VERSION ""

NS_ :

BS_:

BU_: BMS CHG

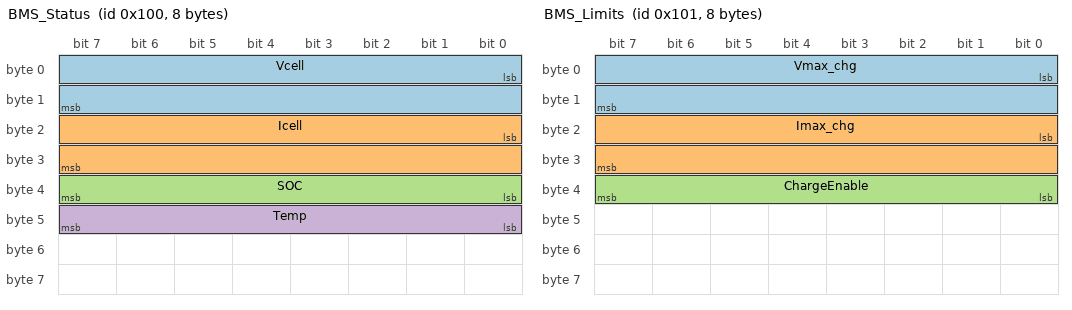
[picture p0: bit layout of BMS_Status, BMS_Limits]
BO_ 256 BMS_Status: 8 BMS
 SG_ Vcell : 0|16@1+ (0.001,0) [0|65.535] "V" CHG
 SG_ Icell : 16|16@1- (0.1,0) [-3276.8|3276.7] "A" CHG
 SG_ SOC : 32|8@1+ (0.5,0) [0|127.5] "%" CHG
 SG_ Temp : 40|8@1+ (1,-40) [-40|215] "degC" CHG

BO_ 257 BMS_Limits: 8 BMS
 SG_ Vmax_chg : 0|16@1+ (0.01,0) [0|655.35] "V" CHG
 SG_ Imax_chg : 16|16@1+ (0.1,0) [0|6553.5] "A" CHG
 SG_ ChargeEnable : 32|8@1+ (1,0) [0|1] "" CHG
